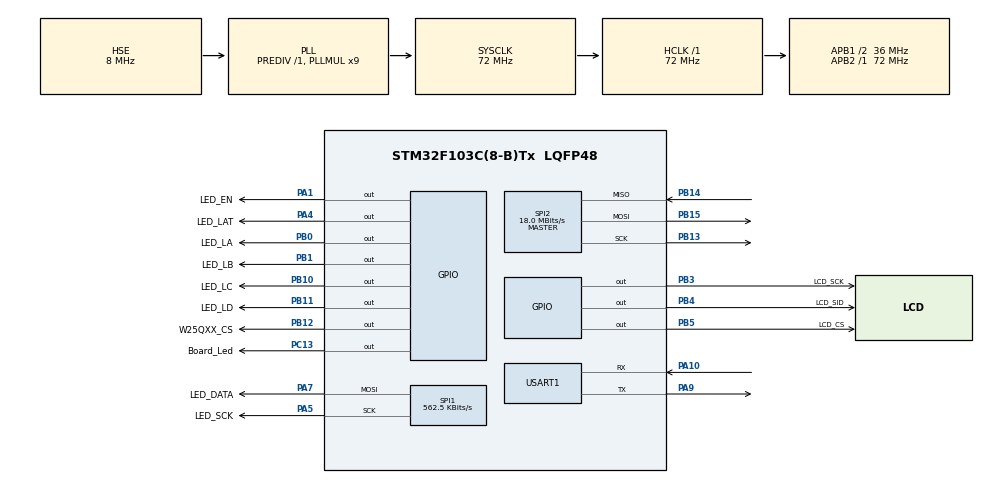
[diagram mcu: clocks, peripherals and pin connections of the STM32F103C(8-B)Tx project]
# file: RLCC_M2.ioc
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Dma.Request0=SPI1_TX
Dma.Request1=USART1_RX
Dma.SPI1_TX.0.Direction=DMA_MEMORY_TO_PERIPH
Dma.SPI1_TX.0.Instance=DMA1_Channel3
Dma.SPI1_TX.0.MemDataAlignment=DMA_MDATAALIGN_BYTE
Dma.SPI1_TX.0.MemInc=DMA_MINC_ENABLE
Dma.SPI1_TX.0.Mode=DMA_NORMAL
Dma.SPI1_TX.0.PeriphDataAlignment=DMA_PDATAALIGN_BYTE
Dma.SPI1_TX.0.PeriphInc=DMA_PINC_DISABLE
Dma.SPI1_TX.0.Priority=DMA_PRIORITY_LOW
Dma.USART1_RX.1.Direction=DMA_PERIPH_TO_MEMORY
Dma.USART1_RX.1.Instance=DMA1_Channel5
Dma.USART1_RX.1.MemDataAlignment=DMA_MDATAALIGN_BYTE
Dma.USART1_RX.1.MemInc=DMA_MINC_ENABLE
Dma.USART1_RX.1.Mode=DMA_CIRCULAR
Dma.USART1_RX.1.PeriphDataAlignment=DMA_PDATAALIGN_BYTE
Dma.USART1_RX.1.PeriphInc=DMA_PINC_DISABLE
Dma.USART1_RX.1.Priority=DMA_PRIORITY_VERY_HIGH
Mcu.Family=STM32F1
Mcu.Name=STM32F103C(8-B)Tx
Mcu.Package=LQFP48
NVIC.DMA1_Channel3_IRQn=true\:0\:0\:false\:false\:true\:false\:true\:true
NVIC.DMA1_Channel5_IRQn=true\:0\:0\:false\:false\:true\:false\:true\:true
NVIC.PriorityGroup=NVIC_PRIORITYGROUP_4
NVIC.TIM2_IRQn=true\:0\:0\:false\:false\:true\:true\:true\:true
NVIC.USART1_IRQn=true\:0\:0\:false\:false\:true\:true\:true\:true
PA1.GPIO_Label=LED_EN
PA1.Signal=GPIO_Output
PA10.Mode=Asynchronous
PA10.Signal=USART1_RX
PA13.Mode=Serial_Wire
PA13.Signal=SYS_JTMS-SWDIO
PA14.Mode=Serial_Wire
PA14.Signal=SYS_JTCK-SWCLK
PA4.GPIO_Label=LED_LAT
PA4.Signal=GPIO_Output
PA5.GPIO_Label=LED_SCK
PA5.Mode=TX_Only_Simplex_Unidirect_Master
PA5.Signal=SPI1_SCK
PA7.GPIO_Label=LED_DATA
PA7.Mode=TX_Only_Simplex_Unidirect_Master
PA7.Signal=SPI1_MOSI
PA9.Mode=Asynchronous
PA9.Signal=USART1_TX
PB0.GPIO_Label=LED_LA
PB0.Signal=GPIO_Output
PB1.GPIO_Label=LED_LB
PB1.Signal=GPIO_Output
PB10.GPIO_Label=LED_LC
PB10.Signal=GPIO_Output
PB11.GPIO_Label=LED_LD
PB11.Signal=GPIO_Output
PB12.GPIO_Label=W25QXX_CS
PB12.Signal=GPIO_Output
PB13.Mode=Full_Duplex_Master
PB13.Signal=SPI2_SCK
PB14.Mode=Full_Duplex_Master
PB14.Signal=SPI2_MISO
PB15.Mode=Full_Duplex_Master
PB15.Signal=SPI2_MOSI
PB3.GPIO_Label=LCD_SCK
PB3.Signal=GPIO_Output
PB4.GPIO_Label=LCD_SID
PB4.Signal=GPIO_Output
PB5.GPIO_Label=LCD_CS
PB5.Signal=GPIO_Output
PC13-TAMPER-RTC.GPIO_Label=Board_Led
PC13-TAMPER-RTC.GPIO_ModeDefaultOutputPP=GPIO_MODE_OUTPUT_PP
PC13-TAMPER-RTC.GPIO_PuPd=GPIO_NOPULL
PC13-TAMPER-RTC.PinState=GPIO_PIN_RESET
PC13-TAMPER-RTC.Signal=GPIO_Output
PC14-OSC32_IN.Mode=LSE-External-Oscillator
PC14-OSC32_IN.Signal=RCC_OSC32_IN
PC15-OSC32_OUT.Mode=LSE-External-Oscillator
PC15-OSC32_OUT.Signal=RCC_OSC32_OUT
PD0-OSC_IN.Mode=HSE-External-Oscillator
PD0-OSC_IN.Signal=RCC_OSC_IN
PD1-OSC_OUT.Mode=HSE-External-Oscillator
PD1-OSC_OUT.Signal=RCC_OSC_OUT
ProjectManager.HeapSize=0x200
ProjectManager.StackSize=0x400
ProjectManager.TargetToolchain=CMake
RCC.AHBFreq_Value=72000000
RCC.APB1CLKDivider=RCC_HCLK_DIV2
RCC.APB1Freq_Value=36000000
RCC.APB1TimFreq_Value=72000000
RCC.APB2Freq_Value=72000000
RCC.APB2TimFreq_Value=72000000
RCC.HCLKFreq_Value=72000000
RCC.PLLMUL=RCC_PLL_MUL9
RCC.PLLSourceVirtual=RCC_PLLSOURCE_HSE
RCC.RTCClockSelection=RCC_RTCCLKSOURCE_LSE
RCC.SYSCLKFreq_VALUE=72000000
RCC.SYSCLKSource=RCC_SYSCLKSOURCE_PLLCLK
RCC.USBFreq_Value=72000000
RTC.AutoPrediv=RTC_AUTO_1_SECOND
RTC.Format=RTC_FORMAT_BIN
SPI1.BaudRatePrescaler=SPI_BAUDRATEPRESCALER_128
SPI1.CalculateBaudRate=562.5 KBits/s
SPI1.Direction=SPI_DIRECTION_2LINES
SPI1.Mode=SPI_MODE_MASTER
SPI1.VirtualType=VM_MASTER
SPI2.CalculateBaudRate=18.0 MBits/s
SPI2.Direction=SPI_DIRECTION_2LINES
SPI2.Mode=SPI_MODE_MASTER
SPI2.VirtualType=VM_MASTER
TIM2.Prescaler=71
USART1.VirtualMode=VM_ASYNC
VP_RTC_VS_RTC_Activate.Mode=RTC_Enabled
VP_RTC_VS_RTC_Calendar.Mode=RTC_Calendar
VP_TIM2_VS_ClockSourceINT.Mode=Internal
board=custom

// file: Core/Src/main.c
/* USER CODE BEGIN Header */
/**
 ******************************************************************************
 * @file           : main.c
 * @brief          : Main program body
 ******************************************************************************
 * @attention
 *
 * Copyright (c) 2026 STMicroelectronics.
 * All rights reserved.
 *
 * This software is licensed under terms that can be found in the LICENSE file
 * in the root directory of this software component.
 * If no LICENSE file comes with this software, it is provided AS-IS.
 *
 ******************************************************************************
 */
/* USER CODE END Header */
#include "main.h"
#include "dma.h"
#include "rtc.h"
#include "spi.h"
#include "tim.h"
#include "usart.h"
#include "gpio.h"

/* USER CODE BEGIN Includes */
#include "app.h"
#include "system_utils.h"
#include <stdio.h>

/* USER CODE END Includes */

void SystemClock_Config(void);

int main(void)
{

  /* MCU Configuration--------------------------------------------------------*/

  /* Reset of all peripherals, Initializes the Flash interface and the Systick. */
  HAL_Init();

  /* Configure the system clock */
  SystemClock_Config();

  /* Initialize all configured peripherals */
  MX_GPIO_Init();
  MX_DMA_Init();
  MX_RTC_Init();
  MX_SPI1_Init();
  MX_SPI2_Init();
  MX_USART1_UART_Init();
  MX_TIM2_Init();
  /* USER CODE BEGIN 2 */
  DWT_Init();
  App_Init();
  printf("System Started!\r\n");

  /* USER CODE END 2 */

  /* Infinite loop */
  /* USER CODE BEGIN WHILE */
  while (1) {
    App_Loop();
    /* USER CODE END WHILE */

  }
}

void SystemClock_Config(void)
{
  RCC_OscInitTypeDef RCC_OscInitStruct = {0};
  RCC_ClkInitTypeDef RCC_ClkInitStruct = {0};
  RCC_PeriphCLKInitTypeDef PeriphClkInit = {0};

  /** Initializes the RCC Oscillators according to the specified parameters
  * in the RCC_OscInitTypeDef structure.
  */
  RCC_OscInitStruct.OscillatorType = RCC_OSCILLATORTYPE_HSE|RCC_OSCILLATORTYPE_LSE;
  RCC_OscInitStruct.HSEState = RCC_HSE_ON;
  RCC_OscInitStruct.HSEPredivValue = RCC_HSE_PREDIV_DIV1;
  RCC_OscInitStruct.LSEState = RCC_LSE_ON;
  RCC_OscInitStruct.HSIState = RCC_HSI_ON;
  RCC_OscInitStruct.PLL.PLLState = RCC_PLL_ON;
  RCC_OscInitStruct.PLL.PLLSource = RCC_PLLSOURCE_HSE;
  RCC_OscInitStruct.PLL.PLLMUL = RCC_PLL_MUL9;
  if (HAL_RCC_OscConfig(&RCC_OscInitStruct) != HAL_OK)
  {
    Error_Handler();
  }

  /** Initializes the CPU, AHB and APB buses clocks
  */
  RCC_ClkInitStruct.ClockType = RCC_CLOCKTYPE_HCLK|RCC_CLOCKTYPE_SYSCLK
                              |RCC_CLOCKTYPE_PCLK1|RCC_CLOCKTYPE_PCLK2;
  RCC_ClkInitStruct.SYSCLKSource = RCC_SYSCLKSOURCE_PLLCLK;
  RCC_ClkInitStruct.AHBCLKDivider = RCC_SYSCLK_DIV1;
  RCC_ClkInitStruct.APB1CLKDivider = RCC_HCLK_DIV2;
  RCC_ClkInitStruct.APB2CLKDivider = RCC_HCLK_DIV1;

  if (HAL_RCC_ClockConfig(&RCC_ClkInitStruct, FLASH_LATENCY_2) != HAL_OK)
  {
    Error_Handler();
  }
  PeriphClkInit.PeriphClockSelection = RCC_PERIPHCLK_RTC;
  PeriphClkInit.RTCClockSelection = RCC_RTCCLKSOURCE_LSE;
  if (HAL_RCCEx_PeriphCLKConfig(&PeriphClkInit) != HAL_OK)
  {
    Error_Handler();
  }
}

/* USER CODE BEGIN 4 */

int __io_putchar(int ch) {
  HAL_UART_Transmit(&huart1, (uint8_t *)&ch, 1, 0xFFFF);
  return ch;
}

/* USER CODE END 4 */

void Error_Handler(void)
{
  __disable_irq();
  while (1) {
  }
}
#ifdef USE_FULL_ASSERT
/**
  * @brief  Reports the name of the source file and the source line number
  *         where the assert_param error has occurred.
  * @param  file: pointer to the source file name
  * @param  line: assert_param error line source number
  * @retval None
  */
void assert_failed(uint8_t *file, uint32_t line)
{
  /* USER CODE BEGIN 6 */
  /* User can add his own implementation to report the file name and line
     number, ex: printf("Wrong parameters value: file %s on line %d\r\n", file,
     line) */
  /* USER CODE END 6 */
}
#endif /* USE_FULL_ASSERT */
